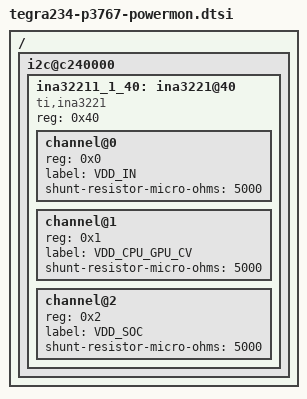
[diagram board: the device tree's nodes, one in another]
/*
 * Copyright (c) 2021-2022, NVIDIA CORPORATION.  All rights reserved.
 *
 * This program is free software; you can redistribute it and/or modify
 * it under the terms of the GNU General Public License as published by
 * the Free Software Foundation; version 2 of the License.
 *
 * This program is distributed in the hope that it will be useful, but WITHOUT
 * ANY WARRANTY; without even the implied warranty of MERCHANTABILITY or
 * FITNESS FOR A PARTICULAR PURPOSE.  See the GNU General Public License for
 * more details.
 */

/ {
	i2c@c240000 {
		ina32211_1_40: ina3221@40 {
			compatible = "ti,ina3221";
			reg = <0x40>;
			#address-cells = <1>;
			#size-cells = <0>;
			#io-channel-cells = <1>;
			channel@0 {
				reg = <0x0>;
				label = "VDD_IN";
				shunt-resistor-micro-ohms = <5000>;
			};
			channel@1 {
				reg = <0x1>;
				label = "VDD_CPU_GPU_CV";
				shunt-resistor-micro-ohms = <5000>;
			};
			channel@2 {
				reg = <0x2>;
				label = "VDD_SOC";
				shunt-resistor-micro-ohms = <5000>;
			};
		};
	};
};
